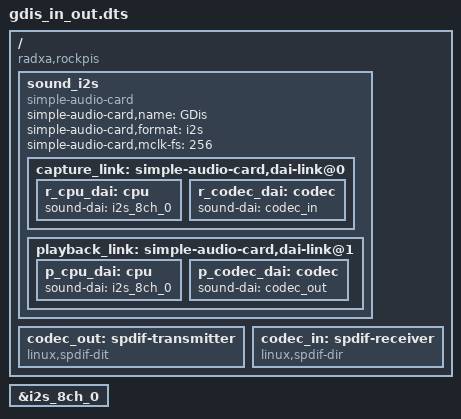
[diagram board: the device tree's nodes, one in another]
/dts-v1/;
/plugin/;

/ {
    compatible = "radxa,rockpis", "rockchip,rk3308";

    fragment@0 {
        target-path = "/";
        __overlay__ {
              sound_i2s {
                     compatible = "simple-audio-card";
                     simple-audio-card,name = "GDis";
                     simple-audio-card,format = "i2s";
                     simple-audio-card,mclk-fs = <256>;
                     status="okay";

                     capture_link: simple-audio-card,dai-link@0 {
                     r_cpu_dai: cpu {
                     sound-dai = <&i2s_8ch_0>;
                };
                     r_codec_dai: codec {
                     sound-dai = <&codec_in>;
                   };
                };

                     playback_link: simple-audio-card,dai-link@1 {
                     p_cpu_dai: cpu {
                     sound-dai = <&i2s_8ch_0>;
                   };
                     p_codec_dai: codec {
                     sound-dai = <&codec_out>;
                   };
                };
            };
        };
    };

    fragment@1 {
        target-path = "/";
        __overlay__ {
            codec_out: spdif-transmitter {
                #address-cells = <0>;
                #size-cells = <0>;
                #sound-dai-cells = <0>;
                compatible = "linux,spdif-dit";
                status = "okay";
            };
            codec_in: spdif-receiver {
                #address-cells = <0>;
                #size-cells = <0>;
                #sound-dai-cells = <0>;
                compatible = "linux,spdif-dir";
                status = "okay";
            };
        };
    };

    fragment@2 {
        target = <&i2s_8ch_0>;
        __overlay__ {
            #sound-dai-cells = <0>;
            status = "okay";
        };
    };
};

/* 
Compile with:
   dtc -@ -H epapr -O dtb -o gdiscodec.dtbo -Wno-unit_address_vs_reg gdiscodec.dts
*/
